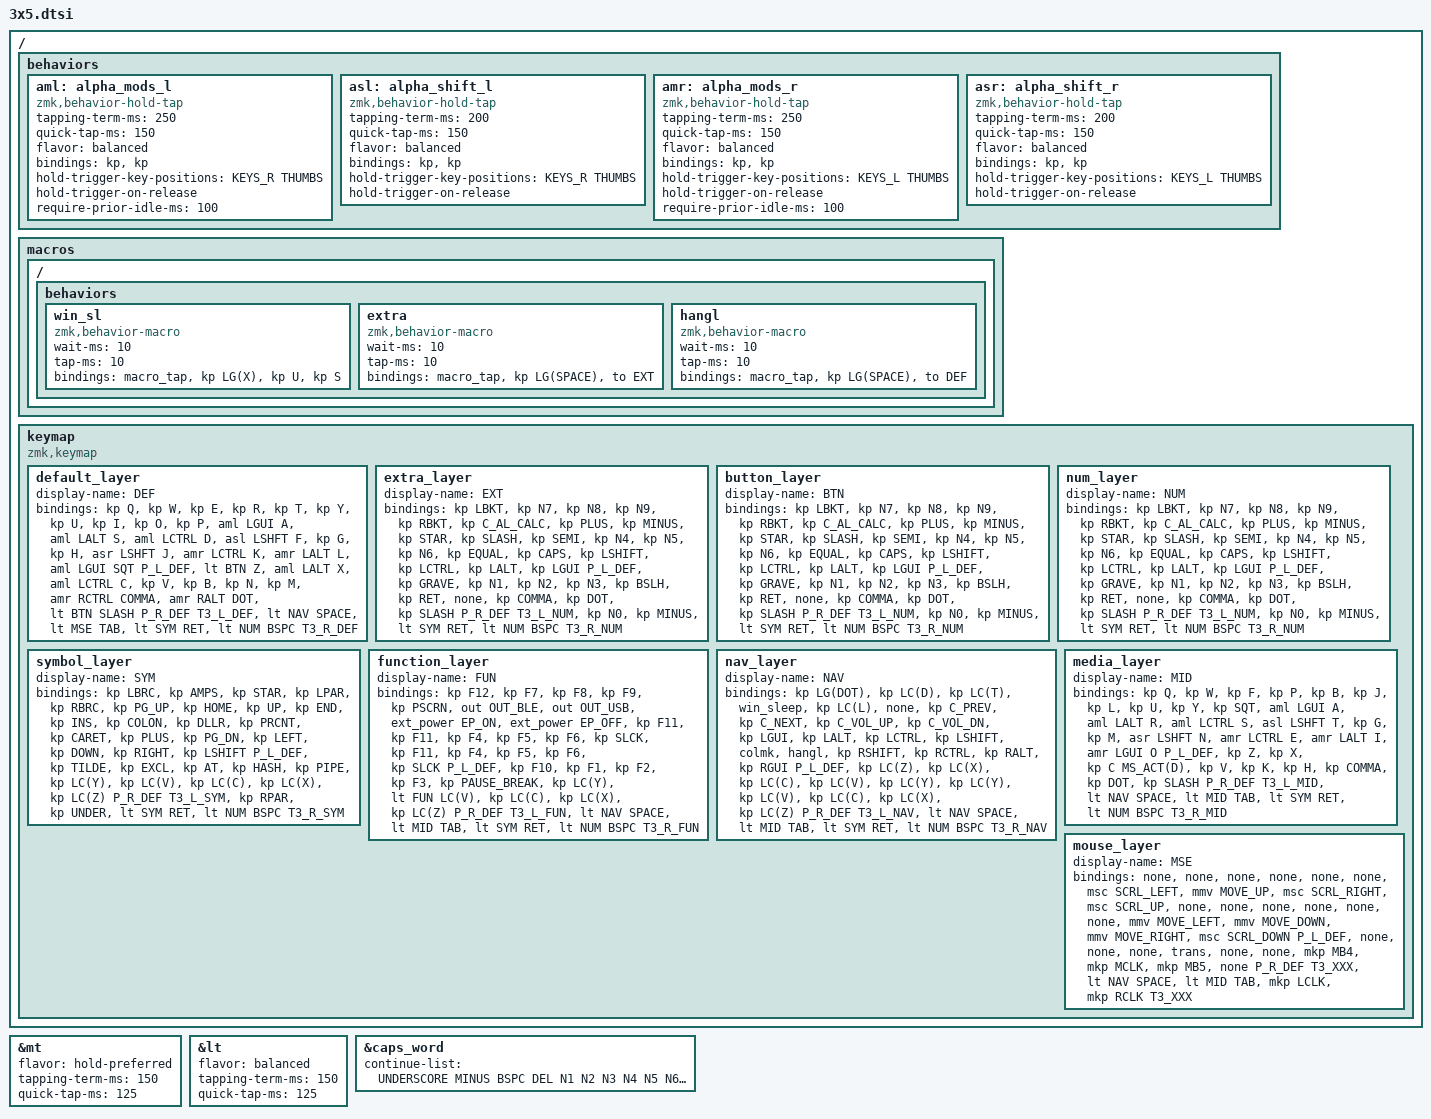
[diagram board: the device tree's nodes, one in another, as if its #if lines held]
#include <behaviors.dtsi>
#include <dt-bindings/zmk/keys.h>
#include <dt-bindings/zmk/bt.h>
#include <dt-bindings/zmk/outputs.h>
#include <dt-bindings/zmk/ext_power.h>


// Layer aliases left thums T0L, right thums T0R
#define DEF 0
#define EXT 1
#define BTN 2
#define NAV 3
#define MID 4
#define NUM 5
#define SYM 6
#define FUN 7
#define MSE 8

// Key position groups and extra key bindings
#ifdef TOTEM38   /* dropped index and pinkies */
#    define KEYS_L 0 1 2 3 4 10 11 12 13 14 20 21 22 23 24 25
#    define KEYS_R 5 6 7 8 9 15 16 17 18 19 26 27 28 29 30 31
#    define P_L_DEF    &kp ESC     /* left pinky             */
#    define P_R_DEF    &kp RET     /* right pinky            */
#    define ALP_XXX    &none
#else
#    define KEYS_L 0 1 2 3 4 10 11 12 13 14 20 21 22 23 24
#    define KEYS_R 5 6 7 8 9 15 16 17 18 19 25 26 27 28 29
#    define P_L_DEF
#    define P_R_DEF
#    define ALP_XXX    &none
#endif

#ifdef THREE_THUMBS
#    ifdef TOTEM38
#        define THUMBS 30 31 32 33 34 35
#    else
#        define THUMBS 32 33 34 35 36 37
#    endif
#    define T3_L_DEF &lt MID ESC
#    define T3_R_DEF &lt FUN DEL
#    define T3_L_NAV
#    define T3_R_NAV &kp DEL
#    define T3_L_MID
#    define T3_R_MID &kp C_MUTE
#    define T3_L_NUM &kp DOT
#    define T3_R_NUM &lt FUN DEL
#    define T3_L_SYM &kp LPAR
#    define T3_R_SYM &lt FUN DEL
#    define T3_L_FUN
#    define T3_R_FUN
#    define T3_XXX   &none
#else
#    ifdef TOTEM38
#        define THUMBS 30 31 32 33
#    else
#        define THUMBS 32 33 34 35
#    endif
#    define T3_L_DEF
#    define T3_R_DEF
#    define T3_L_NAV
#    define T3_R_NAV
#    define T3_L_MID
#    define T3_R_MID
#    define T3_L_NUM
#    define T3_R_NUM
#    define T3_L_SYM
#    define T3_R_SYM
#    define T3_L_FUN
#    define T3_R_FUN
#    define T3_XXX   &none
#endif

// Dongle mode. keyboardname.keymap include #define DONGLE_MODE
#ifdef DONGLE_MODE
#    define mid0        &kp LC(Y)
#    define mid1        &kp LC(V)
#    define mid2        &kp LC(C)
#    define mid3        &kp LC(X)
#    define mid4        &kp LC(Z)
#    define mid5        &none
#    define mid6        &none
#else
#    define mid0        &bt BT_SEL 0
#    define mid1        &bt BT_SEL 1
#    define mid2        &bt BT_SEL 2
#    define mid3        &bt BT_SEL 3
#    define mid4        &bt BT_SEL 4
#    define mid5        &bt BT_CLR
#    define mid6        &bt BT_CLR_ALL
#endif

// #include "combos.dtsi"

#ifdef MOUSE_KEYS
#    include "mouse.dtsi"
#    define MS_ACT(key) &lt MSE key
#else
#    define MS_ACT(key) &kp key
#endif

&mt {
    flavor = "hold-preferred";
    tapping-term-ms = <150>;
    quick-tap-ms = <125>;
};

&lt {
    flavor = "balanced";
    tapping-term-ms = <150>;
    quick-tap-ms = <125>;
};

&caps_word {
    continue-list = <UNDERSCORE MINUS BSPC DEL N1 N2 N3 N4 N5 N6 N7 N8 N9 N0>;
};

/ {
    behaviors {
        aml: alpha_mods_l {
            compatible = "zmk,behavior-hold-tap";
            #binding-cells = <2>;
            tapping-term-ms = <250>;
            quick-tap-ms = <150>;
            flavor = "balanced";
            bindings = <&kp>, <&kp>;
            hold-trigger-key-positions = <KEYS_R THUMBS>;
            hold-trigger-on-release;
            require-prior-idle-ms = <100>;
        };
        asl: alpha_shift_l {
            compatible = "zmk,behavior-hold-tap";
            #binding-cells = <2>;
            tapping-term-ms = <200>;
            quick-tap-ms = <150>;
            flavor = "balanced";
            bindings = <&kp>, <&kp>;
            hold-trigger-key-positions = <KEYS_R THUMBS>;
            hold-trigger-on-release;
        };
        amr: alpha_mods_r {
            compatible = "zmk,behavior-hold-tap";
            #binding-cells = <2>;
            tapping-term-ms = <250>;
            quick-tap-ms = <150>;
            flavor = "balanced";
            bindings = <&kp>, <&kp>;
            hold-trigger-key-positions = <KEYS_L THUMBS>;
            hold-trigger-on-release;
            require-prior-idle-ms = <100>;
        };
        asr: alpha_shift_r {
            compatible = "zmk,behavior-hold-tap";
            #binding-cells = <2>;
            tapping-term-ms = <200>;
            quick-tap-ms = <150>;
            flavor = "balanced";
            bindings = <&kp>, <&kp>;
            hold-trigger-key-positions = <KEYS_L THUMBS>;
            hold-trigger-on-release;
        };
    };

     macros {
        ZMK_MACRO(win_sl,
            wait-ms = <10>;
            tap-ms = <10>;
            bindings
                = <&macro_tap &kp LG(X) &kp U &kp S>;
        )
// 시간및언어>언어및지역>기본설정언어 한국어, 영어(미국) 2가지가 있을 때 작
        ZMK_MACRO(extra,
            wait-ms = <10>;
            tap-ms = <10>;
            bindings
                = <&macro_tap &kp LG(SPACE) &to EXT>;
        )
        ZMK_MACRO(hangl,
            wait-ms = <10>;
            tap-ms = <10>;
            bindings
                = <&macro_tap &kp LG(SPACE) &to DEF>;
        )
    };

    keymap {
        compatible = "zmk,keymap";

        default_layer {
            display-name = "DEF";
            bindings = <
//     ╭─────────────┬─────────────┬─────────────┬─────────────┬─────────────╮   ╭─────────────┬─────────────┬─────────────┬─────────────┬─────────────╮
        &kp Q         &kp W         &kp E         &kp R         &kp T             &kp Y         &kp U         &kp I         &kp O         &kp P            
        &aml LGUI A   &aml LALT S   &aml LCTRL D  &asl LSHFT F  &kp G             &kp H         &asr LSHFT J  &amr LCTRL K  &amr LALT L   &aml LGUI SQT   
P_L_DEF &lt BTN Z     &aml LALT X   &aml LCTRL C  &kp V         &kp B             &kp N         &kp M         &amr RCTRL COMMA &amr RALT DOT &lt BTN SLASH P_R_DEF
                                    T3_L_DEF      &lt NAV SPACE &lt MSE TAB       &lt SYM RET   &lt NUM BSPC  T3_R_DEF
//                                               ╰─────────────┴─────────────╯   ╰─────────────┴─────────────╯
            >;
        };

       extra_layer {
            display-name = "EXT";  // colemakdh
            bindings = <
//     ╭─────────────┬─────────────┬─────────────┬─────────────┬─────────────╮   ╭─────────────┬─────────────┬─────────────┬─────────────┬─────────────╮
         &kp LBKT      &kp N7        &kp N8        &kp N9        &kp RBKT          &kp C_AL_CALC &kp PLUS      &kp MINUS     &kp STAR      &kp SLASH
//     ├─────────────┼─────────────┼─────────────┼─────────────┼─────────────┤   ├─────────────┼─────────────┼─────────────┼─────────────┼─────────────┤
         &kp SEMI      &kp N4        &kp N5        &kp N6        &kp EQUAL         &kp CAPS      &kp LSHIFT    &kp LCTRL     &kp LALT      &kp LGUI
//     ├─────────────┼─────────────┼─────────────┼─────────────┼─────────────┤   ├─────────────┼─────────────┼─────────────┼─────────────┼─────────────┤
P_L_DEF  &kp GRAVE     &kp N1        &kp N2        &kp N3        &kp BSLH          &kp RET       &none         &kp COMMA     &kp DOT       &kp SLASH    P_R_DEF
//     ╰─────────────┴─────────────┴─────────────┼─────────────┼─────────────┤   ├─────────────┼─────────────┼─────────────┴─────────────┴─────────────╯
                                     T3_L_NUM      &kp N0        &kp MINUS         &lt SYM RET   &lt NUM BSPC  T3_R_NUM
//                                               ╰─────────────┴─────────────╯   ╰─────────────┴─────────────╯
            >;
        };

       button_layer {
            display-name = "BTN";  // BTN
            bindings = <
//     ╭─────────────┬─────────────┬─────────────┬─────────────┬─────────────╮   ╭─────────────┬─────────────┬─────────────┬─────────────┬─────────────╮
         &kp LBKT      &kp N7        &kp N8        &kp N9        &kp RBKT          &kp C_AL_CALC &kp PLUS      &kp MINUS     &kp STAR      &kp SLASH
//     ├─────────────┼─────────────┼─────────────┼─────────────┼─────────────┤   ├─────────────┼─────────────┼─────────────┼─────────────┼─────────────┤
         &kp SEMI      &kp N4        &kp N5        &kp N6        &kp EQUAL         &kp CAPS      &kp LSHIFT    &kp LCTRL     &kp LALT      &kp LGUI
//     ├─────────────┼─────────────┼─────────────┼─────────────┼─────────────┤   ├─────────────┼─────────────┼─────────────┼─────────────┼─────────────┤
P_L_DEF  &kp GRAVE     &kp N1        &kp N2        &kp N3        &kp BSLH          &kp RET       &none         &kp COMMA     &kp DOT       &kp SLASH    P_R_DEF
//     ╰─────────────┴─────────────┴─────────────┼─────────────┼─────────────┤   ├─────────────┼─────────────┼─────────────┴─────────────┴─────────────╯
                                     T3_L_NUM      &kp N0        &kp MINUS         &lt SYM RET   &lt NUM BSPC  T3_R_NUM
//                                               ╰─────────────┴─────────────╯   ╰─────────────┴─────────────╯
            >;
        };

       num_layer {
            display-name = "NUM";  // NUM
            bindings = <
//     ╭─────────────┬─────────────┬─────────────┬─────────────┬─────────────╮   ╭─────────────┬─────────────┬─────────────┬─────────────┬─────────────╮
         &kp LBKT      &kp N7        &kp N8        &kp N9        &kp RBKT          &kp C_AL_CALC &kp PLUS      &kp MINUS     &kp STAR      &kp SLASH
//     ├─────────────┼─────────────┼─────────────┼─────────────┼─────────────┤   ├─────────────┼─────────────┼─────────────┼─────────────┼─────────────┤
         &kp SEMI      &kp N4        &kp N5        &kp N6        &kp EQUAL         &kp CAPS      &kp LSHIFT    &kp LCTRL     &kp LALT      &kp LGUI
//     ├─────────────┼─────────────┼─────────────┼─────────────┼─────────────┤   ├─────────────┼─────────────┼─────────────┼─────────────┼─────────────┤
P_L_DEF  &kp GRAVE     &kp N1        &kp N2        &kp N3        &kp BSLH          &kp RET       &none         &kp COMMA     &kp DOT       &kp SLASH    P_R_DEF
//     ╰─────────────┴─────────────┴─────────────┼─────────────┼─────────────┤   ├─────────────┼─────────────┼─────────────┴─────────────┴─────────────╯
                                     T3_L_NUM      &kp N0        &kp MINUS         &lt SYM RET   &lt NUM BSPC  T3_R_NUM
//                                               ╰─────────────┴─────────────╯   ╰─────────────┴─────────────╯
            >;
        };

       symbol_layer {
            display-name = "SYM";  // SYM
            bindings = <
//     ╭─────────────┬─────────────┬─────────────┬─────────────┬─────────────╮   ╭─────────────┬─────────────┬─────────────┬─────────────┬─────────────╮
         &kp LBRC      &kp AMPS      &kp STAR      &kp LPAR      &kp RBRC          &kp PG_UP     &kp HOME      &kp UP        &kp END        &kp INS
//     ├─────────────┼─────────────┼─────────────┼─────────────┼─────────────┤   ├─────────────┼─────────────┼─────────────┼─────────────┼─────────────┤
         &kp COLON     &kp DLLR      &kp PRCNT     &kp CARET     &kp PLUS          &kp PG_DN     &kp LEFT      &kp DOWN      &kp RIGHT      &kp LSHIFT
//     ├─────────────┼─────────────┼─────────────┼─────────────┼─────────────┤   ├─────────────┼─────────────┼─────────────┼─────────────┼─────────────┤
P_L_DEF  &kp TILDE     &kp EXCL      &kp AT        &kp HASH      &kp PIPE          &kp LC(Y)     &kp LC(V)     &kp LC(C)     &kp LC(X)     &kp LC(Z)    P_R_DEF
//     ╰─────────────┴─────────────┴─────────────┼─────────────┼─────────────┤   ├─────────────┼─────────────┼─────────────┴─────────────┴─────────────╯
                                     T3_L_SYM      &kp RPAR      &kp UNDER         &lt SYM RET   &lt NUM BSPC  T3_R_SYM
//                                               ╰─────────────┴─────────────╯   ╰─────────────┴─────────────╯
            >;
        };

        function_layer {
            display-name = "FUN";  // FUN
            bindings = <
//     ╭─────────────┬─────────────┬─────────────┬─────────────┬─────────────╮   ╭─────────────┬─────────────┬─────────────┬─────────────┬─────────────╮
         &kp F12       &kp F7        &kp F8        &kp F9        &kp PSCRN         &out OUT_BLE  &out OUT_USB &ext_power EP_ON &ext_power EP_OFF &kp F11
//     ├─────────────┼─────────────┼─────────────┼─────────────┼─────────────┤   ├─────────────┼─────────────┼─────────────┼─────────────┼─────────────┤
         &kp F11       &kp F4        &kp F5        &kp F6        &kp SLCK          &kp F11       &kp F4        &kp F5        &kp F6        &kp SLCK 
//     ├─────────────┼─────────────┼─────────────┼─────────────┼─────────────┤   ├─────────────┼─────────────┼─────────────┼─────────────┼─────────────┤
P_L_DEF  &kp F10       &kp F1        &kp F2        &kp F3        &kp PAUSE_BREAK   &kp LC(Y)     &lt FUN LC(V) &kp LC(C)     &kp LC(X)     &kp LC(Z)    P_R_DEF
//     ╰─────────────┴─────────────┴─────────────┼─────────────┼─────────────┤   ├─────────────┼─────────────┼─────────────┴─────────────┴─────────────╯
                                     T3_L_FUN      &lt NAV SPACE &lt MID TAB       &lt SYM RET   &lt NUM BSPC T3_R_FUN
//                                               ╰─────────────┴─────────────╯   ╰─────────────┴─────────────╯
            >;
        };

        nav_layer {
            display-name = "NAV";  // NAV
            bindings = <
//     ╭─────────────┬─────────────┬─────────────┬─────────────┬─────────────╮   ╭─────────────┬─────────────┬─────────────┬─────────────┬─────────────╮
         &kp LG(DOT)   &kp LC(D)     &kp LC(T)     &win_sleep    &kp LC(L)         &none         &kp C_PREV    &kp C_NEXT    &kp C_VOL_UP  &kp C_VOL_DN
//     ├─────────────┼─────────────┼─────────────┼─────────────┼─────────────┤   ├─────────────┼─────────────┼─────────────┼─────────────┼─────────────┤
         &kp LGUI      &kp LALT      &kp LCTRL     &kp LSHIFT    &colmk            &hangl        &kp RSHIFT    &kp RCTRL     &kp RALT      &kp RGUI
//     ├─────────────┼─────────────┼─────────────┼─────────────┼─────────────┤   ├─────────────┼─────────────┼─────────────┼─────────────┼─────────────┤
P_L_DEF  &kp LC(Z)     &kp LC(X)     &kp LC(C)     &kp LC(V)     &kp LC(Y)         &kp LC(Y)     &kp LC(V)     &kp LC(C)     &kp LC(X)     &kp LC(Z)    P_R_DEF
//     ╰─────────────┴─────────────┴─────────────┼─────────────┼─────────────┤   ├─────────────┼─────────────┼─────────────┴─────────────┴─────────────╯
                                     T3_L_NAV      &lt NAV SPACE &lt MID TAB       &lt SYM RET   &lt NUM BSPC  T3_R_NAV
//                                               ╰─────────────┴─────────────╯   ╰─────────────┴─────────────╯
            >;
        };

        media_layer {
            display-name = "MID";  // MEDIA
            bindings = <
//     ╭─────────────┬─────────────┬─────────────┬─────────────┬─────────────╮   ╭─────────────┬─────────────┬─────────────┬─────────────┬─────────────╮
         &kp Q         &kp W         &kp F         &kp P         &kp B             &kp J         &kp L         &kp U         &kp Y         &kp SQT
//     ├─────────────┼─────────────┼─────────────┼─────────────┼─────────────┤   ├─────────────┼─────────────┼─────────────┼─────────────┼─────────────┤
         &aml LGUI A   &aml LALT R   &aml LCTRL S  &asl LSHFT T  &kp G             &kp M         &asr LSHFT N  &amr LCTRL E  &amr LALT I   &amr LGUI O
//     ├─────────────┼─────────────┼─────────────┼─────────────┼─────────────┤   ├─────────────┼─────────────┼─────────────┼─────────────┼─────────────┤
P_L_DEF  &kp Z         &kp X         &kp C         MS_ACT(D)     &kp V             &kp K         &kp H         &kp COMMA     &kp DOT       &kp SLASH    P_R_DEF
//     ╰─────────────┴─────────────┴─────────────┼─────────────┼─────────────┤   ├─────────────┼─────────────┼─────────────┴─────────────┴─────────────╯
                                     T3_L_MID     &lt NAV SPACE &lt MID TAB       &lt SYM RET   &lt NUM BSPC  T3_R_MID
//                                               ╰─────────────┴─────────────╯   ╰─────────────┴─────────────╯
            >;
        };

#ifdef MOUSE_KEYS
        mouse_layer {
            display-name = "MSE";    // T2L
            bindings = <
//     ╭─────────────┬─────────────┬─────────────┬─────────────┬─────────────╮   ╭─────────────┬─────────────┬─────────────┬─────────────┬─────────────╮
         &none         &none         &none         &none         &none             &none        &msc SCRL_LEFT &mmv MOVE_UP  &msc SCRL_RIGHT &msc SCRL_UP
//     ├─────────────┼─────────────┼─────────────┼─────────────┼─────────────┤   ├─────────────┼─────────────┼─────────────┼─────────────┼─────────────┤
         &none         &none         &none         &none         &none             &none       &mmv MOVE_LEFT &mmv MOVE_DOWN &mmv MOVE_RIGHT &msc SCRL_DOWN
//     ├─────────────┼─────────────┼─────────────┼─────────────┼─────────────┤   ├─────────────┼─────────────┼─────────────┼─────────────┼─────────────┤
P_L_DEF  &none         &none         &none         &trans        &none             &none         &mkp MB4      &mkp MCLK     &mkp MB5      &none        P_R_DEF
//     ╰─────────────┴─────────────┴─────────────┼─────────────┼─────────────┤   ├─────────────┼─────────────┼─────────────┴─────────────┴─────────────╯
                                     T3_XXX       &lt NAV SPACE &lt MID TAB       &mkp LCLK     &mkp RCLK     T3_XXX
//                                               ╰─────────────┴─────────────╯   ╰─────────────┴─────────────╯
            >;
        };
#endif

    };
};
